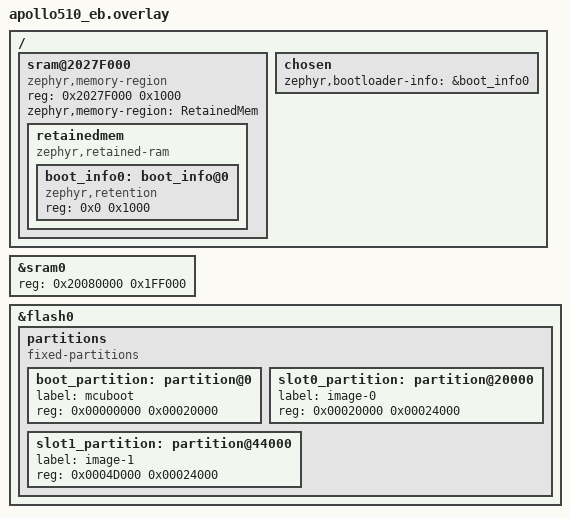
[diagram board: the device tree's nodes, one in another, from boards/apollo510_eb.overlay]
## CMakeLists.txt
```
#
# Copyright (c) 2023 Nordic Semiconductor ASA
#
# SPDX-License-Identifier: Apache-2.0
#

cmake_minimum_required(VERSION 3.28.0)
find_package(Zephyr REQUIRED HINTS $ENV{ZEPHYR_BASE})
project(mcuboot_recovery_retention)

if(NOT (DEFINED SYSBUILD))
  message(FATAL_ERROR "This test must be built with sysbuild.")
endif()

FILE(GLOB app_sources
  src/*.c
)

zephyr_get(sysbuild_binary_dir VAR APPLICATION_BINARY_DIR SYSBUILD GLOBAL)
import_kconfig(SB_CONFIG_BOOT_SIGNATURE_TYPE_* "${sysbuild_binary_dir}/zephyr/.config")

if(SB_CONFIG_BOOT_SIGNATURE_TYPE_ECDSA_P256)
  target_compile_definitions(app PRIVATE EXPECTED_BOOT_SIGNATURE=MCUBOOT_SIGNATURE_TYPE_ECDSA_P256)
elseif(SB_CONFIG_BOOT_SIGNATURE_TYPE_RSA)
  target_compile_definitions(app PRIVATE EXPECTED_BOOT_SIGNATURE=MCUBOOT_SIGNATURE_TYPE_RSA)
elseif(SB_CONFIG_BOOT_SIGNATURE_TYPE_NONE)
  target_compile_definitions(app PRIVATE EXPECTED_BOOT_SIGNATURE=MCUBOOT_SIGNATURE_TYPE_NONE)
elseif(SB_CONFIG_BOOT_SIGNATURE_TYPE_ED25519)
  target_compile_definitions(app PRIVATE EXPECTED_BOOT_SIGNATURE=MCUBOOT_SIGNATURE_TYPE_ED25519)
endif()

target_sources(app PRIVATE ${app_sources})

# Get MCUboot version from the VERSION file in the repository and create a local output header
# version file so that it can be compared against in the test
set(VERSION_FILE ${ZEPHYR_MCUBOOT_MODULE_DIR}/boot/zephyr/VERSION)
set(VERSION_TYPE MCUBOOT)
set(BUILD_VERSION_NAME MCUBOOT_BUILD_VERSION)
include(${ZEPHYR_BASE}/cmake/modules/version.cmake)
file(READ ${ZEPHYR_BASE}/version.h.in version_content)
string(CONFIGURE "${version_content}" version_content)
string(CONFIGURE "${version_content}" version_content)
file(
  WRITE
  ${CMAKE_CURRENT_BINARY_DIR}/zephyr/include/generated/zephyr/mcuboot_version.h
  "${version_content}"
)
```

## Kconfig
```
# Copyright 2026 Nordic Semiconductor ASA
# SPDX-License-Identifier: Apache-2.0

choice
	prompt "Expected signature type passed from MCUboot via retention"
	default TEST_EXPECTED_MCUBOOT_SIGNATURE_TYPE_NONE

config TEST_EXPECTED_MCUBOOT_SIGNATURE_TYPE_ECDSA_P256
	bool "Expected ECDSA P256"

config TEST_EXPECTED_MCUBOOT_SIGNATURE_TYPE_ED25519
	bool "Expected ED25519"

config TEST_EXPECTED_MCUBOOT_SIGNATURE_TYPE_RSA
	bool "Expected RSA"

config TEST_EXPECTED_MCUBOOT_SIGNATURE_TYPE_NONE
	bool "Expected None"

endchoice

source "Kconfig.zephyr"
```

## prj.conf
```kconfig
#
# Copyright (c) 2023 Nordic Semiconductor ASA
#
# SPDX-License-Identifier: Apache-2.0
#
CONFIG_ZTEST=y
CONFIG_RETAINED_MEM=y
CONFIG_RETENTION=y
CONFIG_SETTINGS=y
CONFIG_SETTINGS_RUNTIME=y
CONFIG_RETENTION_BOOTLOADER_INFO=y
CONFIG_RETENTION_BOOTLOADER_INFO_TYPE_MCUBOOT=y
CONFIG_RETENTION_BOOTLOADER_INFO_OUTPUT_SETTINGS=y
```

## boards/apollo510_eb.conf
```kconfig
#
# Copyright (c) 2025, Ambiq Micro Inc. <www.ambiq.com>
#
# SPDX-License-Identifier: Apache-2.0
#
CONFIG_RETAINED_MEM_ZEPHYR_RAM=y
```

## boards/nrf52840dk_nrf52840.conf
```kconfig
#
# Copyright (c) 2023 Nordic Semiconductor ASA
#
# SPDX-License-Identifier: Apache-2.0
#
CONFIG_RETAINED_MEM_NRF_GPREGRET=n
```

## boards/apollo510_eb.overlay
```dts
/*
 * Copyright (c) 2025, Ambiq Micro Inc. <www.ambiq.com>
 *
 * SPDX-License-Identifier: Apache-2.0
 */

/ {
		sram@2027F000 {
		compatible = "zephyr,memory-region", "mmio-sram";
		reg = <0x2027F000 0x1000>;
		zephyr,memory-region = "RetainedMem";
		status = "okay";

		retainedmem {
			compatible = "zephyr,retained-ram";
			status = "okay";
			#address-cells = <1>;
			#size-cells = <1>;

			boot_info0: boot_info@0 {
				compatible = "zephyr,retention";
				status = "okay";
				reg = <0x0 0x1000>;
			};
		};
	};

	chosen {
		zephyr,bootloader-info = &boot_info0;
	};
};


&sram0 {
	/* Shrink SRAM size to avoid overlap with retained memory region:
	 * 2048 - 4 = 2044KB = 0x1FF000
	 */
	reg = <0x20080000 0x1FF000>;
};

/delete-node/ &boot_partition;
/delete-node/ &slot0_partition;
/delete-node/ &slot1_partition;

&flash0 {
	partitions {
		compatible = "fixed-partitions";
		#address-cells = <1>;
		#size-cells = <1>;

		boot_partition: partition@0 {
			label = "mcuboot";
			reg = <0x00000000 0x00020000>;
		};
		/*
		 * The case is not flexible, need to modify the slot_partition
		 * to match the FLASH_MAX_APP_SIZE in the case.
		 */
		slot0_partition: partition@20000 {
			label = "image-0";
			reg = <0x00020000 0x00024000>;
		};
		slot1_partition: partition@44000 {
			label = "image-1";
			reg = <0x0004D000 0x00024000>;
		};
	};
};
```

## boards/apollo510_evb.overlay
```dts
/*
 * Copyright (c) 2025, Ambiq Micro Inc. <www.ambiq.com>
 *
 * SPDX-License-Identifier: Apache-2.0
 */

/ {
		sram@201FF000 {
		compatible = "zephyr,memory-region", "mmio-sram";
		reg = <0x201FF000 0x1000>;
		zephyr,memory-region = "RetainedMem";
		status = "okay";

		retainedmem {
			compatible = "zephyr,retained-ram";
			status = "okay";
			#address-cells = <1>;
			#size-cells = <1>;

			boot_info0: boot_info@0 {
				compatible = "zephyr,retention";
				status = "okay";
				reg = <0x0 0x1000>;
			};
		};
	};

	chosen {
		zephyr,bootloader-info = &boot_info0;
	};
};


&sram0 {
	/* Shrink SRAM size to avoid overlap with retained memory region:
	 * 1536 - 4 = 1532KB = 0x17F000
	 */
	reg = <SSRAM_BASE_ADDR 0x17F000>;
};

/delete-node/ &boot_partition;
/delete-node/ &slot0_partition;
/delete-node/ &slot1_partition;

&flash0 {
	partitions {
		compatible = "fixed-partitions";
		#address-cells = <1>;
		#size-cells = <1>;

		boot_partition: partition@0 {
			label = "mcuboot";
			reg = <0x00000000 0x00020000>;
		};
		/*
		 * The case is not flexible, need to modify the slot_partition
		 * to match the FLASH_MAX_APP_SIZE in the case.
		 */
		slot0_partition: partition@20000 {
			label = "image-0";
			reg = <0x00020000 0x00024000>;
		};
		slot1_partition: partition@44000 {
			label = "image-1";
			reg = <0x00044000 0x00024000>;
		};
	};
};
```

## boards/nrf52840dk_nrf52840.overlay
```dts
/* SPDX-License-Identifier: Apache-2.0 */

/ {
	chosen {
		/delete-property/ zephyr,boot-mode;
	};

	chosen {
		zephyr,bootloader-info = &boot_info0;
	};

	sram@2003fc00 {
		compatible = "zephyr,memory-region", "mmio-sram";
		reg = <0x2003fc00 DT_SIZE_K(1)>;
		zephyr,memory-region = "RetainedMem";
		status = "okay";

		retainedmem {
			compatible = "zephyr,retained-ram";
			#address-cells = <1>;
			#size-cells = <1>;
			status = "okay";

			boot_info0: boot_info@0 {
				compatible = "zephyr,retention";
				reg = <0x0 0x100>;
				status = "okay";
			};
		};
	};
};

/delete-node/ &gpregret1;
/delete-node/ &gpregret2;
/delete-node/ &boot_partition;
/delete-node/ &slot0_partition;
/delete-node/ &slot1_partition;

&sram0 {
	reg = <0x20000000 DT_SIZE_K(255)>;
};

&flash0 {
	partitions {
		boot_partition: partition@0 {
			compatible = "zephyr,mapped-partition";
			reg = <0x00000000 0x00020000>;
			label = "mcuboot";
		};

		slot0_partition: partition@20000 {
			compatible = "zephyr,mapped-partition";
			reg = <0x00020000 0x00022000>;
			label = "image-0";
		};

		slot1_partition: partition@42000 {
			compatible = "zephyr,mapped-partition";
			reg = <0x00042000 0x00023000>;
			label = "image-1";
		};
	};
};
```

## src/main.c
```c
/*
 * Copyright (c) 2023 Nordic Semiconductor ASA
 *
 * SPDX-License-Identifier: Apache-2.0
 */

#include <stdint.h>
#include <stdio.h>
#include <zephyr/ztest.h>
#include <zephyr/kernel.h>
#include <zephyr/settings/settings.h>
#include <bootutil/boot_status.h>
#include <bootutil/image.h>
#include <zephyr/mcuboot_version.h>

#if defined(CONFIG_MCUBOOT_BOOTLOADER_MODE_SWAP_USING_OFFSET)
#define EXPECTED_BOOT_MODE	MCUBOOT_MODE_SWAP_USING_OFFSET
#define FLASH_RESERVED_SECTORS 1
#elif defined(CONFIG_MCUBOOT_BOOTLOADER_MODE_SWAP_USING_MOVE)
#define EXPECTED_BOOT_MODE	MCUBOOT_MODE_SWAP_USING_MOVE
#define FLASH_RESERVED_SECTORS 2
#else
#error Attempting to build test for unrecognized bootloader operation mode.
#endif

#if defined(CONFIG_TEST_EXPECTED_MCUBOOT_SIGNATURE_TYPE_ECDSA_P256)
#define EXPECTED_BOOT_SIGNATURE MCUBOOT_SIGNATURE_TYPE_ECDSA_P256
#elif defined(CONFIG_TEST_EXPECTED_MCUBOOT_SIGNATURE_TYPE_ED25519)
#define EXPECTED_BOOT_SIGNATURE MCUBOOT_SIGNATURE_TYPE_ED25519
#elif defined(CONFIG_TEST_EXPECTED_MCUBOOT_SIGNATURE_TYPE_RSA)
#define EXPECTED_BOOT_SIGNATURE MCUBOOT_SIGNATURE_TYPE_RSA
#elif defined(CONFIG_TEST_EXPECTED_MCUBOOT_SIGNATURE_TYPE_NONE)
#define EXPECTED_BOOT_SIGNATURE MCUBOOT_SIGNATURE_TYPE_NONE
#else
#error Attempting to build test for unrecognized signature type.
#endif

#define FLASH_SECTOR_SIZE 1024
#define FLASH_SECTOR_SIZE_KB 4
#define FLASH_MAX_APP_SECTORS 34
#define FLASH_MAX_APP_SIZE ((FLASH_MAX_APP_SECTORS - FLASH_RESERVED_SECTORS) \
			    * FLASH_SECTOR_SIZE_KB)
#define RUNNING_SLOT 0

ZTEST(mcuboot_shared_data, test_mode)
{
	uint8_t var[1];
	int rc;

	memset(var, 0xff, sizeof(var));
	rc = settings_runtime_get("blinfo/mode", var, sizeof(var));
	zassert_equal(rc, sizeof(var), "Expected data length mismatch");
	zassert_equal(var[0], EXPECTED_BOOT_MODE, "Expected data mismatch");
}

ZTEST(mcuboot_shared_data, test_signature_type)
{
	uint8_t var[1];
	int rc;

	memset(var, 0xff, sizeof(var));
	rc = settings_runtime_get("blinfo/signature_type", var, sizeof(var));
	zassert_equal(rc, sizeof(var), "Expected data length mismatch");
	zassert_equal(var[0], EXPECTED_BOOT_SIGNATURE, "Expected data mismatch");
}

ZTEST(mcuboot_shared_data, test_recovery)
{
	uint8_t var[1];
	int rc;

	memset(var, 0xff, sizeof(var));
	rc = settings_runtime_get("blinfo/recovery", var, sizeof(var));
	zassert_equal(rc, sizeof(var), "Expected data length mismatch");
	zassert_equal(var[0], MCUBOOT_RECOVERY_MODE_NONE, "Expected data mismatch");
}

ZTEST(mcuboot_shared_data, test_running_slot)
{
	uint8_t var[1];
	int rc;

	memset(var, 0xff, sizeof(var));
	rc = settings_runtime_get("blinfo/running_slot", var, sizeof(var));
	zassert_equal(rc, sizeof(var), "Expected data length mismatch");
	zassert_equal(var[0], RUNNING_SLOT, "Expected data mismatch");
}

ZTEST(mcuboot_shared_data, test_bootloader_version)
{
	uint8_t var[8];
	int rc;
	struct image_version *version = (void *)var;

	memset(var, 0xff, sizeof(var));
	rc = settings_runtime_get("blinfo/bootloader_version", var, sizeof(var));
	zassert_equal(rc, sizeof(var), "Expected data length mismatch");

	zassert_equal(version->iv_major, MCUBOOT_VERSION_MAJOR,
		      "Expected version (major) mismatch");
	zassert_equal(version->iv_minor, MCUBOOT_VERSION_MINOR,
		      "Expected version (minor) mismatch");
	zassert_equal(version->iv_revision, MCUBOOT_PATCHLEVEL,
		      "Expected version (patch level) mismatch");
	zassert_equal(version->iv_build_num, 0, "Expected version (build number) mismatch");
}

ZTEST(mcuboot_shared_data, test_max_application_size)
{
	uint8_t var[4];
	uint32_t value;
	int rc;

	memset(var, 0xff, sizeof(var));
	rc = settings_runtime_get("blinfo/max_application_size", var, sizeof(var));
	zassert_equal(rc, sizeof(var), "Expected data length mismatch");
	memcpy(&value, var, sizeof(value));
	value /= FLASH_SECTOR_SIZE;
	zassert_equal(value, FLASH_MAX_APP_SIZE, "Expected data mismatch");
}

ZTEST(mcuboot_shared_data, test_invalid)
{
	uint8_t var[4];
	int rc;

	memset(var, 0xff, sizeof(var));
	rc = settings_runtime_get("blinfo/does_not_exist", var, sizeof(var));
	zassert_not_equal(rc, sizeof(var), "Expected data length (error) mismatch");
	zassert_not_equal(rc, 0, "Expected data length (error) mismatch");
}

ZTEST(mcuboot_shared_data, test_bootloader_version_limited)
{
	uint8_t var[2];
	int rc;

	memset(var, 0xff, sizeof(var));
	rc = settings_runtime_get("blinfo/bootloader_version", var, sizeof(var));
	zassert_not_equal(rc, sizeof(var), "Expected data length mismatch");
}

ZTEST_SUITE(mcuboot_shared_data, NULL, NULL, NULL, NULL, NULL);
```
